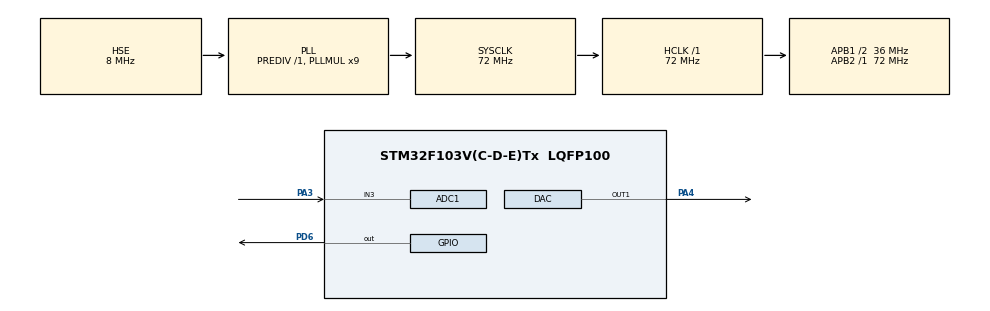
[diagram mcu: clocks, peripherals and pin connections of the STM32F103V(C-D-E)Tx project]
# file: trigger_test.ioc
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ADC1.Channel-4\#ChannelRegularConversion=ADC_CHANNEL_3
ADC1.ContinuousConvMode=ENABLE
ADC1.NbrOfConversion=1
ADC1.NbrOfConversionFlag=1
ADC1.Rank-4\#ChannelRegularConversion=1
ADC1.SamplingTime-4\#ChannelRegularConversion=ADC_SAMPLETIME_28CYCLES_5
ADC1.master=1
DAC.DAC_Trigger=DAC_TRIGGER_T2_TRGO
Dma.DAC_CH1.0.Direction=DMA_MEMORY_TO_PERIPH
Dma.DAC_CH1.0.Instance=DMA2_Channel3
Dma.DAC_CH1.0.MemDataAlignment=DMA_MDATAALIGN_HALFWORD
Dma.DAC_CH1.0.MemInc=DMA_MINC_ENABLE
Dma.DAC_CH1.0.Mode=DMA_CIRCULAR
Dma.DAC_CH1.0.PeriphDataAlignment=DMA_PDATAALIGN_HALFWORD
Dma.DAC_CH1.0.PeriphInc=DMA_PINC_DISABLE
Dma.DAC_CH1.0.Priority=DMA_PRIORITY_LOW
Dma.Request0=DAC_CH1
Mcu.Family=STM32F1
Mcu.Name=STM32F103V(C-D-E)Tx
Mcu.Package=LQFP100
NVIC.DMA2_Channel3_IRQn=true\:0\:0\:false\:false\:true\:false\:true
NVIC.PriorityGroup=NVIC_PRIORITYGROUP_4
NVIC.TIM2_IRQn=true\:6\:0\:true\:false\:true\:true\:true
NVIC.TIM6_IRQn=true\:1\:0\:true\:false\:true\:true\:true
OSC_IN.Mode=HSE-External-Oscillator
OSC_IN.Signal=RCC_OSC_IN
OSC_OUT.Mode=HSE-External-Oscillator
OSC_OUT.Signal=RCC_OSC_OUT
PA13.Mode=JTAG_4_pins
PA13.Signal=SYS_JTMS-SWDIO
PA14.Mode=JTAG_4_pins
PA14.Signal=SYS_JTCK-SWCLK
PA15.Mode=JTAG_4_pins
PA15.Signal=SYS_JTDI
PA3.Signal=ADCx_IN3
PA4.Signal=COMP_DAC1_group
PB3.Mode=JTAG_4_pins
PB3.Signal=SYS_JTDO-TRACESWO
PD6.Signal=GPIO_Output
ProjectManager.HeapSize=0x200
ProjectManager.StackSize=0x400
ProjectManager.TargetToolchain=MDK-ARM V5.27
RCC.ADCPresc=RCC_ADCPCLK2_DIV6
RCC.AHBFreq_Value=72000000
RCC.APB1CLKDivider=RCC_HCLK_DIV2
RCC.APB1Freq_Value=36000000
RCC.APB1TimFreq_Value=72000000
RCC.APB2Freq_Value=72000000
RCC.APB2TimFreq_Value=72000000
RCC.HCLKFreq_Value=72000000
RCC.PLLMUL=RCC_PLL_MUL9
RCC.PLLSourceVirtual=RCC_PLLSOURCE_HSE
RCC.SYSCLKFreq_VALUE=72000000
RCC.SYSCLKSource=RCC_SYSCLKSOURCE_PLLCLK
RCC.USBFreq_Value=72000000
SH.ADCx_IN3.0=ADC1_IN3,IN3
SH.COMP_DAC1_group.0=DAC_OUT1,DAC_OUT1
TIM2.AutoReloadPreload=TIM_AUTORELOAD_PRELOAD_ENABLE
TIM2.Period=10000-1
TIM2.Prescaler=72-1
TIM2.TIM_MasterOutputTrigger=TIM_TRGO_UPDATE
TIM6.Period=10000-1
TIM6.Prescaler=7200-1
VP_TIM2_VS_ClockSourceINT.Mode=Internal
VP_TIM6_VS_ClockSourceINT.Mode=Enable_Timer
board=custom

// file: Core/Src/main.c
/* USER CODE BEGIN Header */
/**
  ******************************************************************************
  * @file           : main.c
  * @brief          : Main program body
  ******************************************************************************
  * @attention
  *
  * <h2><center>&copy; Copyright (c) 2021 STMicroelectronics.
  * All rights reserved.</center></h2>
  *
  * This software component is licensed by ST under BSD 3-Clause license,
  * the "License"; You may not use this file except in compliance with the
  * License. You may obtain a copy of the License at:
  *                        opensource.org/licenses/BSD-3-Clause
  *
  ******************************************************************************
  */
/* USER CODE END Header */
#include "main.h"

/* USER CODE BEGIN Includes */
#include "math.h"

/* USER CODE END Includes */

/* USER CODE BEGIN PD */

#define NUMBER_OF_SAMPLES 50        // TO MAKE SINE SIGNAL
#define duration 10000
#define PI 3.1415
/* USER CODE END PD */

ADC_HandleTypeDef hadc1;

DAC_HandleTypeDef hdac;
DMA_HandleTypeDef hdma_dac_ch1;

TIM_HandleTypeDef htim2;
TIM_HandleTypeDef htim6;

/* USER CODE BEGIN PV */

uint16_t note_length[31] = {duration/8, duration/4, duration/8,
							duration/4, duration/4, duration/4,
							duration/2, duration/4, duration/4, duration/4, duration/4,
							duration/4, duration/4, duration/4,
							duration/2, duration/4, duration/8,duration/4, duration/8,
							duration/4, duration/4,
							duration/4, duration/4, duration/8,duration/4, duration/8,
							duration/4, duration/4, duration/4, duration/2,
							duration};

uint16_t converted_notes[7][31] = { //-------------------------------------------------
													{32, 1, 32,
													36, 32, 43,
													41, 1, 32, 1, 32, 							//octave1
													36, 32, 49,
													43, 1, 32, 1, 32,
													55, 43,
													41, 36, 32, 1, 32,
													55, 43, 49, 43,
													1}, //-------------------------------------------------
													{65, 1 ,65,
													73, 65, 87,
													82, 1, 65, 1, 65, 							//octave2
													73, 65, 98,
													87, 1, 65, 1, 65,
													110, 87,
													82, 73, 65, 1, 65,
													110, 87, 98, 87,
													1}, //-------------------------------------------------
													{130, 1, 130,
													147, 130, 174,
													165, 1, 130, 1, 130, 							//octave3
													147, 130, 196,
													174, 1, 130, 1, 130,
													220, 174,
													165, 147, 130, 1, 130,
													220, 174, 196, 174,
													1}, //-------------------------------------------------
														{261, 1, 261,
													293, 261, 350,
													330, 1, 261, 1, 261,
													293, 261, 391,
													350, 1, 261, 1, 261, 							//octave4
													440, 350,
                          330, 293, 261, 1, 261,
													440, 350, 391, 350,
													1}, //-------------------------------------------------
													{523, 1, 523,
													587, 523, 698,
													659, 1, 523, 1, 523, 							//octave5
													587, 523, 783,
													698, 1, 523, 1, 523,
													880, 698,
													659, 587, 523, 1, 523,
													880, 698, 783, 698,
													1}, //-------------------------------------------------
													{1040, 1, 1040,
													1174, 1040, 1390,
													1310, 1, 1040, 1, 1040, 						//octave6
													1170, 1040, 1570,
													1390, 1, 1040, 1,  1040,
													1760, 1390,
													1310, 1170, 1040,  1, 1040,
													1760, 1390, 1570, 1390,
													1}, //-------------------------------------------------
													{2080, 1, 2080,
													2348, 2080, 2780,
													2620, 1, 2080, 1, 2080, 						//octave7
													2340, 2080, 3140,
													2780, 1, 2080, 1,  2080,
													3520, 2780,
													2620, 2340, 2080,  1, 2080,
													3520, 2780, 3140, 2780,
													1} //-------------------------------------------------
};

uint16_t converted_note[31] = {261, 1, 261, // default values are for octave 4 since it starts from octave 4
													293, 261, 350,
													330, 1, 261, 1, 261,
													293, 261, 391,
													350, 1, 261, 1, 261,
													440, 350,
                          330, 293, 261, 1,261,
													440, 350, 391, 350,
													1};

uint32_t adc_reset = 0;
uint8_t octave_number = 4;
uint8_t note_number = 0;
uint16_t ADC_VALUE = 0;
uint16_t sine[NUMBER_OF_SAMPLES];

/* USER CODE END PV */

void SystemClock_Config(void);
static void MX_GPIO_Init(void);
static void MX_DMA_Init(void);
static void MX_DAC_Init(void);
static void MX_TIM2_Init(void);
static void MX_TIM6_Init(void);
static void MX_ADC1_Init(void);

int main(void)
{

  /* MCU Configuration--------------------------------------------------------*/

  /* Reset of all peripherals, Initializes the Flash interface and the Systick. */
  HAL_Init();

  /* Configure the system clock */
  SystemClock_Config();

  /* Initialize all configured peripherals */
  MX_GPIO_Init();
  MX_DMA_Init();
  MX_DAC_Init();
  MX_TIM2_Init();
  MX_TIM6_Init();
  MX_ADC1_Init();
  /* USER CODE BEGIN 2 */
	for(uint8_t i=1; i<=NUMBER_OF_SAMPLES; i+=1)
		sine[i] = (uint16_t)(((sin(2*PI/NUMBER_OF_SAMPLES*(i)))*4095)-1); // 12 bits

	HAL_TIM_Base_Start(&htim2);
	HAL_DAC_Start_DMA(&hdac, DAC_CHANNEL_1, (uint32_t*) sine, NUMBER_OF_SAMPLES, DAC_ALIGN_12B_R);
	HAL_TIM_Base_Start_IT(&htim6);

	HAL_ADC_Start(&hadc1);

  /* USER CODE END 2 */

  /* Infinite loop */
  while (1)
  {

    /* USER CODE BEGIN 3 */
		if(adc_reset == 1)
		{

			ADC_VALUE = HAL_ADC_GetValue(&hadc1);
			octave_number = (uint8_t) (ADC_VALUE*7/4094);
			switch(octave_number)
    {
        case 0:
            for(uint8_t i = 0; i<31; i+=1)
							converted_note[i] = converted_notes[0][i];
            break;

        case 1:
           for(uint8_t i = 0; i<31; i+=1)
						converted_note[i] = converted_notes[1][i];
            break;

        case 2:
            for(uint8_t i = 0; i<31; i+=1)
							converted_note[i] = converted_notes[2][i];
            break;

        case 3:
            for(uint8_t i = 0; i<31; i+=1)
							converted_note[i] = converted_notes[3][i];
            break;
				case 4:
            for(uint8_t i = 0; i<31; i+=1)
							converted_note[i] = converted_notes[4][i];
            break;
				case 5:
            for(uint8_t i = 0; i<31; i+=1)
							converted_note[i] = converted_notes[5][i];
            break;
				case 6:
            for(uint8_t i = 0; i<31; i+=1)
							converted_note[i] = converted_notes[6][i];
            break;
        default:
            for(uint8_t i = 0; i<31; i+=1)
							converted_note[i] = converted_notes[4][i];
            break;
    }

			adc_reset = 0;
		}
		HAL_Delay(10);
  }
}

void HAL_TIM_PeriodElapsedCallback(TIM_HandleTypeDef *htim)
{
  if(htim-> Instance == TIM6)
	{
		TIM2->ARR = (uint16_t) 50000/converted_note[note_number];
		TIM6->ARR = note_length[note_number];
		note_number += 1;
		if(note_number == 31)
		{
			note_number = 0;
			adc_reset = 1;
		}
	}
}

  /* USER CODE END 3 */

void SystemClock_Config(void)
{
  RCC_OscInitTypeDef RCC_OscInitStruct = {0};
  RCC_ClkInitTypeDef RCC_ClkInitStruct = {0};
  RCC_PeriphCLKInitTypeDef PeriphClkInit = {0};

  /** Initializes the RCC Oscillators according to the specified parameters
  * in the RCC_OscInitTypeDef structure.
  */
  RCC_OscInitStruct.OscillatorType = RCC_OSCILLATORTYPE_HSE;
  RCC_OscInitStruct.HSEState = RCC_HSE_ON;
  RCC_OscInitStruct.HSEPredivValue = RCC_HSE_PREDIV_DIV1;
  RCC_OscInitStruct.HSIState = RCC_HSI_ON;
  RCC_OscInitStruct.PLL.PLLState = RCC_PLL_ON;
  RCC_OscInitStruct.PLL.PLLSource = RCC_PLLSOURCE_HSE;
  RCC_OscInitStruct.PLL.PLLMUL = RCC_PLL_MUL9;
  if (HAL_RCC_OscConfig(&RCC_OscInitStruct) != HAL_OK)
  {
    Error_Handler();
  }
  /** Initializes the CPU, AHB and APB buses clocks
  */
  RCC_ClkInitStruct.ClockType = RCC_CLOCKTYPE_HCLK|RCC_CLOCKTYPE_SYSCLK
                              |RCC_CLOCKTYPE_PCLK1|RCC_CLOCKTYPE_PCLK2;
  RCC_ClkInitStruct.SYSCLKSource = RCC_SYSCLKSOURCE_PLLCLK;
  RCC_ClkInitStruct.AHBCLKDivider = RCC_SYSCLK_DIV1;
  RCC_ClkInitStruct.APB1CLKDivider = RCC_HCLK_DIV2;
  RCC_ClkInitStruct.APB2CLKDivider = RCC_HCLK_DIV1;

  if (HAL_RCC_ClockConfig(&RCC_ClkInitStruct, FLASH_LATENCY_2) != HAL_OK)
  {
    Error_Handler();
  }
  PeriphClkInit.PeriphClockSelection = RCC_PERIPHCLK_ADC;
  PeriphClkInit.AdcClockSelection = RCC_ADCPCLK2_DIV6;
  if (HAL_RCCEx_PeriphCLKConfig(&PeriphClkInit) != HAL_OK)
  {
    Error_Handler();
  }
}

static void MX_ADC1_Init(void)
{

  ADC_ChannelConfTypeDef sConfig = {0};

  /** Common config
  */
  hadc1.Instance = ADC1;
  hadc1.Init.ScanConvMode = ADC_SCAN_DISABLE;
  hadc1.Init.ContinuousConvMode = ENABLE;
  hadc1.Init.DiscontinuousConvMode = DISABLE;
  hadc1.Init.ExternalTrigConv = ADC_SOFTWARE_START;
  hadc1.Init.DataAlign = ADC_DATAALIGN_RIGHT;
  hadc1.Init.NbrOfConversion = 1;
  if (HAL_ADC_Init(&hadc1) != HAL_OK)
  {
    Error_Handler();
  }
  /** Configure Regular Channel
  */
  sConfig.Channel = ADC_CHANNEL_3;
  sConfig.Rank = ADC_REGULAR_RANK_1;
  sConfig.SamplingTime = ADC_SAMPLETIME_28CYCLES_5;
  if (HAL_ADC_ConfigChannel(&hadc1, &sConfig) != HAL_OK)
  {
    Error_Handler();
  }

}

static void MX_DAC_Init(void)
{

  DAC_ChannelConfTypeDef sConfig = {0};

  /** DAC Initialization
  */
  hdac.Instance = DAC;
  if (HAL_DAC_Init(&hdac) != HAL_OK)
  {
    Error_Handler();
  }
  /** DAC channel OUT1 config
  */
  sConfig.DAC_Trigger = DAC_TRIGGER_T2_TRGO;
  sConfig.DAC_OutputBuffer = DAC_OUTPUTBUFFER_ENABLE;
  if (HAL_DAC_ConfigChannel(&hdac, &sConfig, DAC_CHANNEL_1) != HAL_OK)
  {
    Error_Handler();
  }

}

static void MX_TIM2_Init(void)
{

  TIM_ClockConfigTypeDef sClockSourceConfig = {0};
  TIM_MasterConfigTypeDef sMasterConfig = {0};

  htim2.Instance = TIM2;
  htim2.Init.Prescaler = 72-1;
  htim2.Init.CounterMode = TIM_COUNTERMODE_UP;
  htim2.Init.Period = 10000-1;
  htim2.Init.ClockDivision = TIM_CLOCKDIVISION_DIV1;
  htim2.Init.AutoReloadPreload = TIM_AUTORELOAD_PRELOAD_ENABLE;
  if (HAL_TIM_Base_Init(&htim2) != HAL_OK)
  {
    Error_Handler();
  }
  sClockSourceConfig.ClockSource = TIM_CLOCKSOURCE_INTERNAL;
  if (HAL_TIM_ConfigClockSource(&htim2, &sClockSourceConfig) != HAL_OK)
  {
    Error_Handler();
  }
  sMasterConfig.MasterOutputTrigger = TIM_TRGO_UPDATE;
  sMasterConfig.MasterSlaveMode = TIM_MASTERSLAVEMODE_DISABLE;
  if (HAL_TIMEx_MasterConfigSynchronization(&htim2, &sMasterConfig) != HAL_OK)
  {
    Error_Handler();
  }

}

static void MX_TIM6_Init(void)
{

  TIM_MasterConfigTypeDef sMasterConfig = {0};

  htim6.Instance = TIM6;
  htim6.Init.Prescaler = 7200-1;
  htim6.Init.CounterMode = TIM_COUNTERMODE_UP;
  htim6.Init.Period = 10000-1;
  htim6.Init.AutoReloadPreload = TIM_AUTORELOAD_PRELOAD_DISABLE;
  if (HAL_TIM_Base_Init(&htim6) != HAL_OK)
  {
    Error_Handler();
  }
  sMasterConfig.MasterOutputTrigger = TIM_TRGO_RESET;
  sMasterConfig.MasterSlaveMode = TIM_MASTERSLAVEMODE_DISABLE;
  if (HAL_TIMEx_MasterConfigSynchronization(&htim6, &sMasterConfig) != HAL_OK)
  {
    Error_Handler();
  }

}

static void MX_DMA_Init(void)
{

  /* DMA controller clock enable */
  __HAL_RCC_DMA2_CLK_ENABLE();

  /* DMA interrupt init */
  /* DMA2_Channel3_IRQn interrupt configuration */
  HAL_NVIC_SetPriority(DMA2_Channel3_IRQn, 0, 0);
  HAL_NVIC_EnableIRQ(DMA2_Channel3_IRQn);

}

static void MX_GPIO_Init(void)
{
  GPIO_InitTypeDef GPIO_InitStruct = {0};

  /* GPIO Ports Clock Enable */
  __HAL_RCC_GPIOA_CLK_ENABLE();
  __HAL_RCC_GPIOD_CLK_ENABLE();
  __HAL_RCC_GPIOB_CLK_ENABLE();

  /*Configure GPIO pin Output Level */
  HAL_GPIO_WritePin(GPIOD, GPIO_PIN_6, GPIO_PIN_RESET);

  /*Configure GPIO pin : PD6 */
  GPIO_InitStruct.Pin = GPIO_PIN_6;
  GPIO_InitStruct.Mode = GPIO_MODE_OUTPUT_PP;
  GPIO_InitStruct.Pull = GPIO_NOPULL;
  GPIO_InitStruct.Speed = GPIO_SPEED_FREQ_LOW;
  HAL_GPIO_Init(GPIOD, &GPIO_InitStruct);

}

void Error_Handler(void)
{
}

/************************ (C) COPYRIGHT STMicroelectronics *****END OF FILE****/
